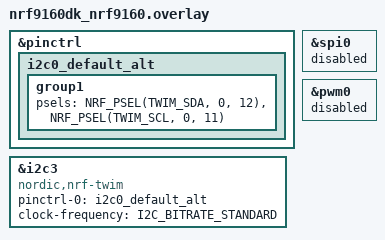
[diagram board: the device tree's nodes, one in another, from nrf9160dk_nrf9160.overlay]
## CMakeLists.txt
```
#
# Copyright (c) 2022 Nordic Semiconductor ASA
#
# SPDX-License-Identifier: LicenseRef-Nordic-5-Clause
#

cmake_minimum_required(VERSION 3.20.0)

find_package(Zephyr REQUIRED HINTS $ENV{ZEPHYR_BASE})
project(nrf_cloud_mqtt_multi_service)

# NORDIC SDK APP START
target_sources(app PRIVATE src/main.c)
target_sources(app PRIVATE src/application.c)
target_sources(app PRIVATE src/connection.c)
target_sources(app PRIVATE src/temperature.c)
target_sources(app PRIVATE src/fota_support.c)
target_sources(app PRIVATE src/location_tracking.c)
target_sources(app PRIVATE src/particulate_matter.c)
target_sources(app PRIVATE src/sht40.c)
target_sources(app PRIVATE src/dfr_no2_co.c)


# NORDIC SDK APP END

zephyr_include_directories(src)
```

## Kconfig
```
#
# Copyright (c) 2022 Nordic Semiconductor ASA
#
# SPDX-License-Identifier: LicenseRef-Nordic-5-Clause
#

menu "MQTT Multi Service Sample Settings"

config POWER_SAVING_MODE_ENABLE
	bool "Enable Power Saving Mode (PSM)"
	help
	  Enable to request Power Saving Mode from cellular network.

config LTE_INIT_RETRY_TIMEOUT_SECONDS
	int "LTE initialization retry timeout (seconds)"
	default 30
	help
	  Sets the number of seconds between each LTE modem initialization
	  retry.

config CLOUD_CONNECTION_RETRY_TIMEOUT_SECONDS
	int "Cloud connection retry timeout (seconds)"
	default 30
	help
	  If connecting to nRF Cloud takes longer than this timeout, it will be
	  reattempted.

config CLOUD_CONNECTION_REESTABLISH_DELAY_SECONDS
	int "Cloud connection reestablishment delay (seconds)"
	default 5
	help
	  After the connection to nRF Cloud has been reset, wait this amount of
	  time before attempting to connect again.

config CLOUD_READY_TIMEOUT_SECONDS
	int "Cloud readiness timeout (seconds)"
	default 600
	help
	  If the connection to nRF Cloud does not become ready within this
	  timeout, the sample will reset its connection and try again.

config DATE_TIME_ESTABLISHMENT_TIMEOUT_SECONDS
	int "Modem date and time establishment timeout (seconds)"
	default 300
	help
	  The sample will wait this many seconds for the modem to determine the
	  current date and time before giving up and moving on.

config APPLICATION_THREAD_STACK_SIZE
	int "Application Thread Stack Size (bytes)"
	default 2048
	help
	  Sets the stack size (in bytes) for the application thread of the
	  sample.

config CONNECTION_THREAD_STACK_SIZE
	int "Connection Thread Stack Size (bytes)"
	default 2048
	help
	  Sets the stack size (in bytes) for the connection thread of the
	  sample.

config MESSAGE_THREAD_STACK_SIZE
	int "Message Queue Thread Stack Size (bytes)"
	default 2048
	help
	  Sets the stack size (in bytes) for the message queue processing
	  thread of the sample.

config MAX_OUTGOING_MESSAGES
	int "Outgoing message maximum"
	default 64
	help
	  Sets the maximum number of device messages which may be enqueued
	  before further messages are dropped.

config MAX_CONSECUTIVE_SEND_FAILURES
	int "Max outgoing consecutive send failures"
	default 5
	help
	  Sets the maximum number of device messages which may fail to send
	  before a connection reset and cooldown is triggered.

config CONSECUTIVE_SEND_FAILURE_COOLDOWN_SECONDS
	int "Cooldown after max consecutive send failures exceeded"
	default 10
	help
	  If a connection reset is triggered by too many failed device
	  messages, the sample will wait this long (in seconds) before trying
	  again.

config SENSOR_SAMPLE_INTERVAL_SECONDS
	int "Sensor sampling interval (seconds)"
	default 6
	help
	  Sets the time to wait between each sensor sample.

config LOCATION_TRACKING_SAMPLE_INTERVAL_SECONDS
	int "Location sampling interval (seconds)"
	default 60
	help
	  Sets the location sampling interval in seconds.

config LOCATION_TRACKING_GNSS
	bool "Use GNSS method for location tracking"
	default y
	depends on LOCATION_METHOD_GNSS
	help
	  Disable both this and LOCATION_TRACKING_CELLULAR to completely disable location tracking.

config LOCATION_TRACKING_CELLULAR
	bool "Use cellular method for location tracking"
	default y
	depends on LOCATION_METHOD_CELLULAR
	help
	  Disable both this and LOCATION_TRACKING_GNSS to completely disable location tracking.

config TEMP_DATA_USE_SENSOR
	bool "Use genuine temperature data"
	depends on BOARD_THINGY91_NRF9160_NS
	default y if BOARD_THINGY91_NRF9160_NS
	select SENSOR
	select BME680
	help
	  Sets whether to take genuine temperature measurements from a
	  connected BME680 sensor, or just simulate sensor data.

config TEMP_TRACKING
	bool "Track temperature"
	default y
	help
	  Sets whether to take temperature measurements.

choice GNSS_ANTENNA
	default GNSS_ANTENNA_ONBOARD
	prompt "Select which antenna to use for GNSS"

config GNSS_ANTENNA_ONBOARD
	bool "Use onboard antenna"

config GNSS_ANTENNA_EXTERNAL
	bool "Use external antenna"

endchoice

config GNSS_AT_MAGPIO
	string "AT%XMAGPIO command"
	default "AT\%XMAGPIO=1,0,0,1,1,1574,1577" if BOARD_NRF9160DK_NRF9160_NS
	default "AT\%XMAGPIO=1,1,1,7,1,746,803,2,698,748,2,1710,2200,3,824,894,4,880,960,5,791,849,7,1565,1586" if BOARD_THINGY91_NRF9160_NS
	help
	  AT%XMAGPIO command to be sent to GNSS module.

config GNSS_AT_COEX0
	string "AT%XCOEX0 command"
	default "AT\%XCOEX0=1,1,1565,1586" if (BOARD_NRF9160DK_NRF9160_NS || BOARD_THINGY91_NRF9160_NS) && GNSS_ANTENNA_ONBOARD
	default "AT\%XCOEX0" if (BOARD_NRF9160DK_NRF9160_NS || BOARD_THINGY91_NRF9160_NS) && GNSS_ANTENNA_EXTERNAL
	help
	  AT%XCOEX0 command to be sent to GNSS module.

config GNSS_FIX_TIMEOUT_SECONDS
	int "GNSS Fix timeout"
	default 40
	help
	  On each location sample, try for this long to achieve a GNSS fix
	  before falling back to cellular positioning.
	  Set this to 20 or so seconds below the sensor sample interval so
	  that there is time left over to perform cellular positioning.
	  Otherwise, location samples may occur at a longer interval than
	  requested.

config TEST_COUNTER
	bool "Sets whether the test counter is enabled"

endmenu

module = MQTT_MULTI_SERVICE
module-str = MQTT Multi Service
source "${ZEPHYR_BASE}/subsys/logging/Kconfig.template.log_config"

menu "Zephyr Kernel"
source "Kconfig.zephyr"
endmenu
```

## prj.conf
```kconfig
#
# Copyright (c) 2022 Nordic Semiconductor ASA
#
# SPDX-License-Identifier: LicenseRef-Nordic-5-Clause
#

# Log level
# For more verbose and detailed log output, set the log level to
# CONFIG_MQTT_MULTI_SERVICE_LOG_LEVEL_DBG=y instead.
CONFIG_MQTT_MULTI_SERVICE_LOG_LEVEL_INF=y

# General config
CONFIG_EVENTS=y
CONFIG_NEWLIB_LIBC=y
CONFIG_NEWLIB_LIBC_FLOAT_PRINTF=y
CONFIG_RESET_ON_FATAL_ERROR=y
CONFIG_NCS_SAMPLES_DEFAULTS=y

# Heap and stacks
# Extended memory heap size needed both for PGPS and for encoding JSON-based nRF Cloud Device Messages
CONFIG_HEAP_MEM_POOL_SIZE=24576
CONFIG_SYSTEM_WORKQUEUE_STACK_SIZE=2048

# Network
CONFIG_NETWORKING=y
CONFIG_NET_NATIVE=n
CONFIG_NET_SOCKETS=y
CONFIG_NET_SOCKETS_OFFLOAD=y

# Modem library
CONFIG_NRF_MODEM_LIB=y

# AT commands interface
CONFIG_UART_INTERRUPT_DRIVEN=y
CONFIG_AT_HOST_LIBRARY=y

# nRF Cloud
CONFIG_NRF_CLOUD_MQTT=y # This also enables FOTA by implicitly setting CONFIG_NRF_CLOUD_FOTA=y

# MQTT
CONFIG_MQTT_KEEPALIVE=120

# MCUBOOT - Needed by FOTA
CONFIG_BOOTLOADER_MCUBOOT=y
CONFIG_IMG_MANAGER=y
CONFIG_MCUBOOT_IMG_MANAGER=y
CONFIG_STREAM_FLASH_ERASE=y

# Location Services configuration
CONFIG_LOCATION=y
CONFIG_LOCATION_METHOD_GNSS=y
CONFIG_LOCATION_METHOD_CELLULAR=y
CONFIG_NRF_CLOUD_AGPS=y
CONFIG_NRF_CLOUD_CELL_POS=y
CONFIG_MULTICELL_LOCATION_SERVICE_NRF_CLOUD=y
CONFIG_MODEM_INFO=y
CONFIG_MODEM_INFO_ADD_NETWORK=y
CONFIG_NRF_CLOUD_PGPS=y
CONFIG_NRF_CLOUD_PGPS_REPLACEMENT_THRESHOLD=4
CONFIG_NRF_CLOUD_PGPS_REQUEST_UPON_INIT=y

# Date Time lib - Used by PGPS and main application
CONFIG_DATE_TIME=y

# LTE link control - used by PGPS and main application
CONFIG_LTE_LINK_CONTROL=y
CONFIG_LTE_NETWORK_MODE_LTE_M_GPS=y
CONFIG_LTE_AUTO_INIT_AND_CONNECT=n

# Settings - used by nRF Cloud library and PGPS
CONFIG_SETTINGS=y
CONFIG_SETTINGS_FCB=y
CONFIG_FCB=y

# Download Client - used by FOTA and PGPS
CONFIG_DOWNLOAD_CLIENT=y
CONFIG_DOWNLOAD_CLIENT_HTTP_FRAG_SIZE_1024=y
CONFIG_DOWNLOAD_CLIENT_STACK_SIZE=4096
CONFIG_DOWNLOAD_CLIENT_BUF_SIZE=2300
CONFIG_DOWNLOAD_CLIENT_MAX_HOSTNAME_SIZE=128

# Flash - Used by FOTA and PGPS
CONFIG_FLASH=y
CONFIG_FLASH_PAGE_LAYOUT=y
CONFIG_FLASH_MAP=y
CONFIG_STREAM_FLASH=y
CONFIG_MPU_ALLOW_FLASH_WRITE=y

# Adding I2C
CONFIG_I2C=y

CONFIG_TIMING_FUNCTIONS=y
CONFIG_CBPRINTF_FP_A_SUPPORT=y
```

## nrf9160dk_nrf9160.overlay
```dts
// To get started, press Ctrl+Space to bring up the completion menu and view the available nodes.
// For more help, browse the DeviceTree documentation at https://docs.zephyrproject.org/latest/guides/dts/index.html

&pinctrl {
    i2c0_default_alt: i2c0_default_alt {
       group1 {
          psels = <NRF_PSEL(TWIM_SDA, 0, 12)>,
                  <NRF_PSEL(TWIM_SCL, 0, 11)>;
       };
    };

 };

&i2c3 {
	status = "okay";
    compatible = "nordic,nrf-twim";
    pinctrl-0 = <&i2c0_default_alt>;
    pinctrl-names = "default";
    // pinctrl-1 = <&i2c0_sleep_alt>; 
    clock-frequency = <I2C_BITRATE_STANDARD>;  
};

/* These two lines are probably not needed below as I'm not using
   i2c0 */
&spi0 {
	status = "disabled";
};

&pwm0 {
	status = "disabled";
};
```

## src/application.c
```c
/* Copyright (c) 2022 Nordic Semiconductor ASA
 *
 * SPDX-License-Identifier: LicenseRef-Nordic-5-Clause
 */

#include <zephyr/kernel.h>
#include <zephyr/logging/log.h>
#include <modem/location.h>
#include <net/nrf_cloud.h>
#include "nrf_cloud_codec.h"
#include <stdio.h>
#include <date_time.h>
#include <cJSON.h>
#include <math.h>
#include <zephyr.h>		/* Give access to k_msleep() */
#include <device.h>		/* Gives access to device_get_bindings() */
#include <devicetree.h> /* For DT macros */
#include <drivers/i2c.h>

#include "application.h"
#include "temperature.h"
#include "connection.h"
#include "location_tracking.h"

#include "particulate_matter.h"
#include "sht40.h"

#define I2C3_NODE DT_NODELABEL(i2c3) /* I2C1_NODE = i2c1 defined in the .dts file */
#if DT_NODE_HAS_STATUS(I2C3_NODE, okay)
#define I2C3 DT_LABEL(I2C3_NODE)
/* A build error here means your board does not have I2C enabled. */
#else "i2c3 devicetree node is disabled"
#define I2C3 ""
#endif

LOG_MODULE_REGISTER(application, CONFIG_MQTT_MULTI_SERVICE_LOG_LEVEL);

/* Timer used to time the sensor sampling rate. */
static K_TIMER_DEFINE(sensor_sample_timer, NULL, NULL);

/**
 * @brief Construct a data device message cJSON object with automatically generated timestamp.
 *
 * @param appid
 * @return cJSON* - the timestamped data device message object if successful, NULL otherwise.
 */
static cJSON *create_timestamped_data_message_object(const char *const appid)
{
	cJSON *msg_obj = NULL;
	int64_t timestamp;

	if (date_time_now(&timestamp))
	{
		LOG_ERR("Failed to create timestamp for data message "
				"with appid %s",
				log_strdup(appid));
		return NULL;
	}

	msg_obj = cJSON_CreateObject();
	if (msg_obj == NULL)
	{
		LOG_ERR("Failed to create container object for timestamped data message "
				"with appid %s",
				log_strdup(appid));
		return NULL;
	}

	/* This structure corresponds to the General Message Schema described in the
	 * application-protocols repo:
	 * https://github.com/nRFCloud/application-protocols
	 */

	if ((cJSON_AddStringToObject(msg_obj, NRF_CLOUD_JSON_APPID_KEY, appid) == NULL) ||
		(cJSON_AddStringToObject(msg_obj, NRF_CLOUD_JSON_MSG_TYPE_KEY,
								 NRF_CLOUD_JSON_MSG_TYPE_VAL_DATA) == NULL) ||
		(cJSON_AddNumberToObject(msg_obj, NRF_CLOUD_MSG_TIMESTAMP_KEY,
								 (double)timestamp) == NULL))
	{
		LOG_ERR("Failed to populate timestamped data message object "
				"with appid %s",
				log_strdup(appid));
		cJSON_Delete(msg_obj);
		return NULL;
	}

	return msg_obj;
}

/**
 * @brief Transmit a collected sensor sample to nRF Cloud.
 *
 * @param sensor - The name of the sensor which was sampled.
 * @param value - The sampled sensor value.
 * @return int - 0 on success, negative error code otherwise.
 */
static int send_sensor_sample(const char *const sensor, double value)
{
	int ret = 0;

	/* Create a timestamped message container object for the sensor sample. */
	cJSON *msg_obj = create_timestamped_data_message_object(sensor);

	if (msg_obj == NULL)
	{
		ret = -EINVAL;
		goto cleanup;
	}

	/* Populate the container object with the sensor value. */
	if (cJSON_AddNumberToObject(msg_obj, NRF_CLOUD_JSON_DATA_KEY, value) == NULL)
	{
		ret = -ENOMEM;
		LOG_ERR("Failed to append value to %s sample container object ",
				log_strdup(sensor));
		goto cleanup;
	}

	/* Send the sensor sample container object as a device message. */
	ret = send_device_message_cJSON(msg_obj);

cleanup:
	if (msg_obj)
	{
		cJSON_Delete(msg_obj);
	}
	return ret;
}

/**
 * @brief Transmit a collected GNSS sample to nRF Cloud.
 *
 * @param NMEA - The raw MNEA value to send to nRF Cloud.
 * @return int - 0 on success, negative error code otherwise.
 */
static int send_gnss_nmea(const char *const nmea)
{
	int ret = 0;

	/* Create a timestamped message container object for the GNSS NMEA data. */
	cJSON *msg_obj = create_timestamped_data_message_object(NRF_CLOUD_JSON_APPID_VAL_GPS);

	if (!msg_obj)
	{
		ret = -EINVAL;
		goto cleanup;
	}

	/* Populate the container object with the NMEA data. */
	if (cJSON_AddStringToObject(msg_obj, NRF_CLOUD_JSON_DATA_KEY, nmea) == NULL)
	{
		ret = -ENOMEM;
		LOG_ERR("Failed to append NMEA data to GNSS message object");
		goto cleanup;
	}

	/* Send the sensor sample container object as a device message. */
	ret = send_device_message_cJSON(msg_obj);

cleanup:
	if (msg_obj)
	{
		cJSON_Delete(msg_obj);
	}
	return ret;
}

/**
 * @brief Compute checksum for NMEA string.
 *
 * @param datastring - The NMEA string to compute the checksum for.
 * @return uint8_t - The resultant checksum.
 */
static uint8_t nmea_checksum(const char *const datastring)
{
	uint8_t checksum = 0;
	int len = strlen(datastring);

	for (int i = 0; i < len; i++)
	{
		checksum ^= datastring[i];
	}
	return checksum;
}

/**
 * @brief Callback to receive periodic location updates from location_tracking.c and forward them
 * to nRF Cloud.
 *
 * Note that cellular positioning (MCELL/Multi-Cell and SCELL/Single-Cell) is sent to nRF
 * Cloud automatically (since the Location library and nRF Cloud must work together to
 * determine them in the first place). GNSS positions, on the other hand, must be
 * sent manually, since they are determined entirely on-device.
 *
 * @param location_data - The received location update.
 *
 */
static void on_location_update(const struct location_data location_data)
{
	LOG_INF("Location Updated: %.06f N %.06f W, accuracy: %.01f m, Method: %s",
			location_data.latitude, location_data.longitude, location_data.accuracy,
			location_data.method == LOCATION_METHOD_CELLULAR ? "Cellular" : location_data.method == LOCATION_METHOD_GNSS ? "GNSS"
																		: location_data.method == LOCATION_METHOD_WIFI	 ? "WIFI"
																														 : "Invalid");

	/* If the position update was derived using GNSS, send it onward to nRF Cloud. */
	if (location_data.method == LOCATION_METHOD_GNSS)
	{
		LOG_INF("GNSS Position Update! Sending to nRF Cloud...");

		/* Synthesize an NMEA message from the provided lat/long/timestamp.
		 * This is necessary, because the nRF Cloud MQTT API only supports NMEA messages.
		 */

		char nmea_buf[50];
		int lat_deg = floor(fabs(location_data.latitude));
		int lon_deg = floor(fabs(location_data.longitude));
		double lat_min = (fabs(location_data.latitude) - lat_deg) * 60;
		double lon_min = (fabs(location_data.longitude) - lon_deg) * 60;

		/* Not actually a valid NMEA,
		 * but close enough that nRF Cloud can't tell the difference.
		 */
		snprintf(nmea_buf, sizeof(nmea_buf), "$GPGGA,,%02d%08.5f,%c,%02d%08.5f,%c,,,,,,,,,",
				 lat_deg, lat_min, location_data.latitude > 0 ? 'N' : 'S',
				 lon_deg, lon_min, location_data.longitude > 0 ? 'E' : 'W');

		int payload_length = strlen(nmea_buf);

		snprintf(nmea_buf + payload_length, sizeof(nmea_buf) - payload_length, "*%02X\n",
				 nmea_checksum(nmea_buf + 1));
		LOG_DBG("NMEA: %s", log_strdup(nmea_buf));

		/* Send the NMEA string. */
		send_gnss_nmea(nmea_buf);
	}
}

void main_application(void)
{
	int ret = 0;
	static int init = 0;

	const struct device *dev_i2c3 = device_get_binding(I2C3);

	pm_data pmReading;
	sht40_data sht40Reading;

	/* Wait for the date and time to become known.
	 * This is needed both for location services and for sensor sample timestamping.
	 */
	LOG_INF("Waiting for modem to determine current date and time");
	if (!await_date_time_known(K_SECONDS(CONFIG_DATE_TIME_ESTABLISHMENT_TIMEOUT_SECONDS)))
	{
		LOG_WRN("Failed to determine valid date time. Proceeding anyways");
	}
	else
	{
		LOG_INF("Current date and time determined");
	}

	/* Begin tracking location at the configured interval. */
	(void)start_location_tracking(on_location_update,
								  CONFIG_LOCATION_TRACKING_SAMPLE_INTERVAL_SECONDS);

	int counter = 0;

	/* Begin sampling sensors. */
	while (true)
	{
		/* Start the sensor sample interval timer.
		 * We use a timer here instead of merely sleeping the thread, because the
		 * application thread can be preempted by other threads performing long tasks
		 * (such as periodic location acquisition), and we want to account for these
		 * delays when metering the sample send rate.
		 */
		k_timer_start(&sensor_sample_timer,
					  K_SECONDS(CONFIG_SENSOR_SAMPLE_INTERVAL_SECONDS), K_FOREVER);

		// if (IS_ENABLED(CONFIG_TEMP_TRACKING))
		// {
		// 	double temp = -1;

		// 	if (get_temperature(&temp) == 0)
		// 	{
		// 		LOG_INF("Temperature is %d degrees C", (int)temp);
		// 		(void)send_sensor_sample(NRF_CLOUD_JSON_APPID_VAL_TEMP, temp);
		// 	}
		// }

		if (pm_read(dev_i2c3, &pmReading) == 0)
		{
			printf("PM 2.5: %d\n", pmReading.pm25_env);
			(void)send_sensor_sample("pm2.5", pmReading.pm25_env);
		}

		if (sht40_read(dev_i2c3, &sht40Reading) == 0)
		{
			printf("T: %lf, H: %lf\n", sht40Reading.temperature, sht40Reading.humidity);
			(void)send_sensor_sample("Temp", sht40Reading.temperature);
			(void)send_sensor_sample("Humidity", sht40Reading.humidity);
		}

		if (IS_ENABLED(CONFIG_TEST_COUNTER))
		{
			(void)send_sensor_sample("COUNT", counter++);
		}

		/* Wait out any remaining time on the sample interval timer. */
		k_timer_status_sync(&sensor_sample_timer);
	}
}
```

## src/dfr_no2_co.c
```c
#include <zephyr/kernel.h>
#include <zephyr.h>     /* Give access to k_msleep() */
#include <device.h>     /* Gives access to device_get_bindings() */
#include <devicetree.h> /* For DT macros */
#include <zephyr/logging/log.h>
#include <drivers/i2c.h>

#include <stdio.h>
#include <zephyr/timing/timing.h>

#include "dfr_no2_co.h"

bool getGasData(const struct device *dev_i2c, dfr_data *dfr_data)
{
    getSensorData(dev_i2c, dfr_data);

    dfr_data->no2 = getNitrogenDioxide(dfr_data);
    dfr_data->co = getCarbonMonoxide(dfr_data);

    return false;
}

float getNitrogenDioxide(dfr_data *dfr_data)
{
    if (dfr_data->RS_R0_OX_data < 1.1)
        return 0;
    float nitrogendioxide = (dfr_data->RS_R0_OX_data - 0.045) / 6.13;
    if (nitrogendioxide < 0.1)
        return 0.0;
    if (nitrogendioxide > 10.0)
        return 10.0;
    return nitrogendioxide;
}

float getCarbonMonoxide(dfr_data *dfr_data)
{
    if (dfr_data->RS_R0_RED_data > 0.425)
        return 0.0;
    float co = (0.425 - dfr_data->RS_R0_RED_data) / 0.000405;
    if (co > 1000.0)
        return 1000.0;
    if (co < 1.0)
        return 0.0;
    return co;
}

bool dfrWakeUp(const struct device *dev_i2c)
{
    int ret = 0;
    uint8_t mode[1] = {0x00};
    uint8_t regData[2] = {POWER_MODE_REGISTER, WAKE_UP_MODE};

    printf("Checking sleep mode\n");

    ret = i2c_write(dev_i2c, regData, 1, MICS_ADDRESS_3);
    if (ret != 0)
    {
        printf("Failed to write I2C device address (err %i)\n", ret);
        return true;
    }

    ret = i2c_read(dev_i2c, mode, 1, MICS_ADDRESS_3);
    if (ret != 0)
    {
        printf("Failed to write I2C device address (err %i)\n", ret);
        return true;
    }

    /* Device is sleeping*/
    if (mode[0] == 0)
    {
        ret = i2c_write(dev_i2c, regData, 2, MICS_ADDRESS_3);
        if (ret != 0)
        {
            printf("Failed to write I2C device address SLEEP (err %i)\n", ret);
            return true;
        }
        printf("Wake sensor up\n");
        k_msleep(100);
    }
    else
    {
        printf("Device is woken up\n");
    }
    return 0;
}

int16_t getSensorData(const struct device *dev_i2c, dfr_data *dfr_data)
{
    int ret = 0;
    int wb[1] = {OX_REGISTER_HIGH};
    uint8_t recv_data[20] = {0x00};

    ret = i2c_write_read(dev_i2c, MICS_ADDRESS_3, wb, 1, recv_data, 6);
    if (ret != 0)
    {
        printf("Failed to write I2C device address for getting sensor data (err %i)\n", ret);
        return ERROR;
    }

    dfr_data->oxData = (((uint16_t)recv_data[0] << 8) + (uint16_t)recv_data[1]);
    dfr_data->redData = (((uint16_t)recv_data[2] << 8) + (uint16_t)recv_data[3]);
    dfr_data->powerData = (((uint16_t)recv_data[4] << 8) + (uint16_t)recv_data[5]);

    dfr_data->r0_ox = dfr_data->powerData - dfr_data->oxData;
    dfr_data->r0_red = dfr_data->powerData - dfr_data->redData;
    // printf("__r0_ox = %d, __r0_red = %d, powerData = %d, oxData = %d, redData = %d\n", dfr_data->r0_ox, dfr_data->r0_red, dfr_data->powerData, dfr_data->oxData, dfr_data->redData);

    dfr_data->RS_R0_RED_data = (float)(dfr_data->powerData - dfr_data->redData) / (float)dfr_data->r0_red;
    dfr_data->RS_R0_OX_data = (float)(dfr_data->powerData - dfr_data->oxData) / (float)dfr_data->r0_ox;

    return 0;
}

bool dfrWarmUpTime(const struct device *dev_i2c, dfr_data *dfr_data)
{
    static timing_t start_time, current_time;
    uint64_t delayTime = 60000000000;
    uint64_t total_cycles;
    uint64_t total_ns;
    static uint8_t flag = 0;

    if (flag == 0)
    {
        flag = 1;
        current_time = 0;
        timing_init();
        timing_start();
        start_time = timing_counter_get();
    }

    current_time = timing_counter_get();

    total_cycles = timing_cycles_get(&start_time, &current_time);
    total_ns = timing_cycles_to_ns(total_cycles);
    // printf("Elapsed Time = %llu\n", total_ns);
    if (total_ns < delayTime)
    {
        return false;
    }

    flag = 0;
    timing_stop();

    if (getSensorData(dev_i2c, dfr_data) == ERROR)
    {
        return false;
    }

    return true;
}
```

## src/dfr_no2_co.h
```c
#ifndef _DFR_NO2_CO_H_
#define _DFR_NO2_CO_H_

#define MICS_ADDRESS_3 0x78

#define CO 0x01	 ///< Carbon Monoxide
#define NO2 0x0A ///< Nitrogen Dioxide
#define POWER_MODE_REGISTER 0x0a
#define SLEEP_MODE 0x00
#define WAKE_UP_MODE 0x01
#define CALIBRATION_TIME 3 // Default calibration time is three minutes
#define ERROR -1
#define OX_REGISTER_HIGH 0x04

#include <device.h>		/* Gives access to device_get_bindings() */


typedef struct dfr_reading
{
    float no2;  ///< Temperature reading
    float co;       ///< Humidity reading
    int16_t r0_ox;
    int16_t r0_red;
    uint16_t oxData;
    uint16_t redData;
    uint16_t powerData;
    float RS_R0_RED_data;
    float RS_R0_OX_data;
} dfr_data;

bool dfrWakeUp(const struct device *dev_i2c);
bool dfrWarmUpTime(const struct device *dev_i2c, dfr_data *dfr_data);
int16_t getSensorData(const struct device *dev_i2c, dfr_data *dfr_data);
bool getGasData(const struct device *dev_i2c, dfr_data *dfr_data);
float getNitrogenDioxide(dfr_data *dfr_data);
float getCarbonMonoxide(dfr_data *dfr_data);
#endif /* _DFR_NO2_CO_H_ */
```

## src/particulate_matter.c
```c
#include <zephyr/kernel.h>
#include <zephyr.h>     /* Give access to k_msleep() */
#include <device.h>     /* Gives access to device_get_bindings() */
#include <devicetree.h> /* For DT macros */
#include <zephyr/logging/log.h>
#include <drivers/i2c.h>

#include "particulate_matter.h"

bool pm_read(const struct device *dev_i2c, pm_data *data)
{
    int ret;
    uint8_t pm_buffer[32] = {0};


    ret = i2c_write_read(dev_i2c, PM_ADDR, PM_SC1, 0, &pm_buffer, 32);
    if (ret != 0)
    {
        // printf("Failed to write/read I2C device address (err %i)\n", ret);
        return true;
    }

    // Check that start byte is correct!
    if (pm_buffer[0] != 0x42)
    {
        return true;
    }

    uint16_t buffer_u16[12];
    for (uint8_t i = 0; i < 12; i++)
    {
        buffer_u16[i] = pm_buffer[2 + i * 2 + 1];
        buffer_u16[i] += (pm_buffer[2 + i * 2] << 8);
    }

    data->pm10_standard = buffer_u16[0];
    data->pm25_standard = buffer_u16[1];
    data->pm100_standard = buffer_u16[2];
    data->pm10_env = buffer_u16[3];
    data->pm25_env = buffer_u16[4];
    data->pm100_env = buffer_u16[5];
    data->particles_03um = buffer_u16[6]; 
    data->particles_05um =  buffer_u16[7];
    data->particles_10um =  buffer_u16[8];
    data->particles_25um =  buffer_u16[9];
    data->particles_50um =  buffer_u16[10];
    data->particles_100um =  buffer_u16[11];

    return false;
}
```

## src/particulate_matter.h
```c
#ifndef _PARTICULATE_MATTER_H_
#define _PARTICULATE_MATTER_H_

#define PM_ADDR 0x12

#define PM_SC1 0x00
#define DATA5_HIGH 0x0C
#define DATA5_LOW 0x0D

#include <device.h>		/* Gives access to device_get_bindings() */

typedef struct pm_reading
{
    uint16_t pm10_standard,  ///< Standard PM1.0
        pm25_standard,       ///< Standard PM2.5
        pm100_standard;      ///< Standard PM10.0
    uint16_t pm10_env,       ///< Environmental PM1.0
        pm25_env,            ///< Environmental PM2.5
        pm100_env;           ///< Environmental PM10.0
    uint16_t particles_03um, ///< 0.3um Particle Count
        particles_05um,      ///< 0.5um Particle Count
        particles_10um,      ///< 1.0um Particle Count
        particles_25um,      ///< 2.5um Particle Count
        particles_50um,      ///< 5.0um Particle Count
        particles_100um;     ///< 10.0um Particle Count
} pm_data;

/**
 * @brief Take a reading from the particulate matter sensor.
 *
 * The readings will report back the pm1.0, pm2.5 and pm10 factory values and environmental
 * value. Along with the
 *
 * @param[out] temp - Pointer to the double to be filled with the taken temperature sample.
 * @return int - 0 on success, otherwise, negative error code.
 */
bool pm_read(const struct device *dev_i2c, pm_data *data);

#endif /* _PARTICULATE_MATTER_H_ */
```

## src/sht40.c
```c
#include <zephyr/kernel.h>
#include <zephyr.h>     /* Give access to k_msleep() */
#include <device.h>     /* Gives access to device_get_bindings() */
#include <devicetree.h> /* For DT macros */
#include <zephyr/logging/log.h>
#include <drivers/i2c.h>
#include <stdio.h>

#include "sht40.h"

bool sht40_read(const struct device *dev_i2c, sht40_data *data)
{
    int ret;
    uint8_t sht40_buffer[6] = {0};
	float t_ticks, rh_ticks = 0;
    uint8_t test[1] = {0xFD};

    ret = i2c_write(dev_i2c, test, 1, SHT40_ADDR);
    if (ret != 0)
    {
    	printf("Failed to write I2C device address (err %i)\n", ret);
    	return true;
    }

    k_msleep(10);

    ret = i2c_read(dev_i2c, sht40_buffer, 6, SHT40_ADDR);
    if (ret != 0)
    {
    	printf("Failed to read I2C device address (err %i)\n", ret);
    	return true;
    }

    t_ticks = (uint16_t)sht40_buffer[0] * 256 + (uint16_t)sht40_buffer[1];
    rh_ticks = (uint16_t)sht40_buffer[3] * 256 + (uint16_t)sht40_buffer[4];

    data->temperature = -45 + 175 * t_ticks / 65535;
    data->humidity = -6 + 125 * rh_ticks / 65535;

    return false;
}
```

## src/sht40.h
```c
#ifndef _SHT40_H_
#define _SHT40_H_

#define SHT40_ADDR	0x44
#define SHT40_HP	0xFD

#include <device.h>		/* Gives access to device_get_bindings() */

typedef struct sht40_reading
{
    double temperature;  ///< Temperature reading
    double humidity;       ///< Humidity reading
} sht40_data;

/**
 * @brief Take a reading from the particulate matter sensor.
 *
 * The readings will report back the pm1.0, pm2.5 and pm10 factory values and environmental
 * value. Along with the
 *
 * @param[out] temp - Pointer to the double to be filled with the taken temperature sample.
 * @return int - 0 on success, otherwise, negative error code.
 */
bool sht40_read(const struct device *dev_i2c, sht40_data *data);

#endif /* _SHT40_H_ */
```
